AUTOSAR XML (schema 00051)
package /Components
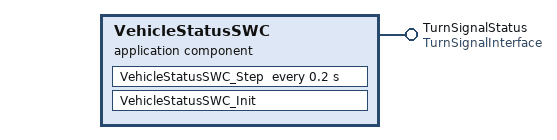
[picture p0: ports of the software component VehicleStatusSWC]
  application sw component type VehicleStatusSWC
    provide port TurnSignalStatus: nonqueued-sender-com-spec{data-element=status, init-value=NONE}, provided-interface=TurnSignalInterface
    behavior VehicleStatusSWC_IB: handle-termination-and-restart=NO-SUPPORT
      timing event Event: start-on-event=VehicleStatusSWC_Step, period=0.2
      runnable VehicleStatusSWC_Init
      runnable VehicleStatusSWC_Step: symbol=New
        data-write-access:
          access OUT_TurnSignalStatus_status: accessed-variable=TurnSignalStatus.status
